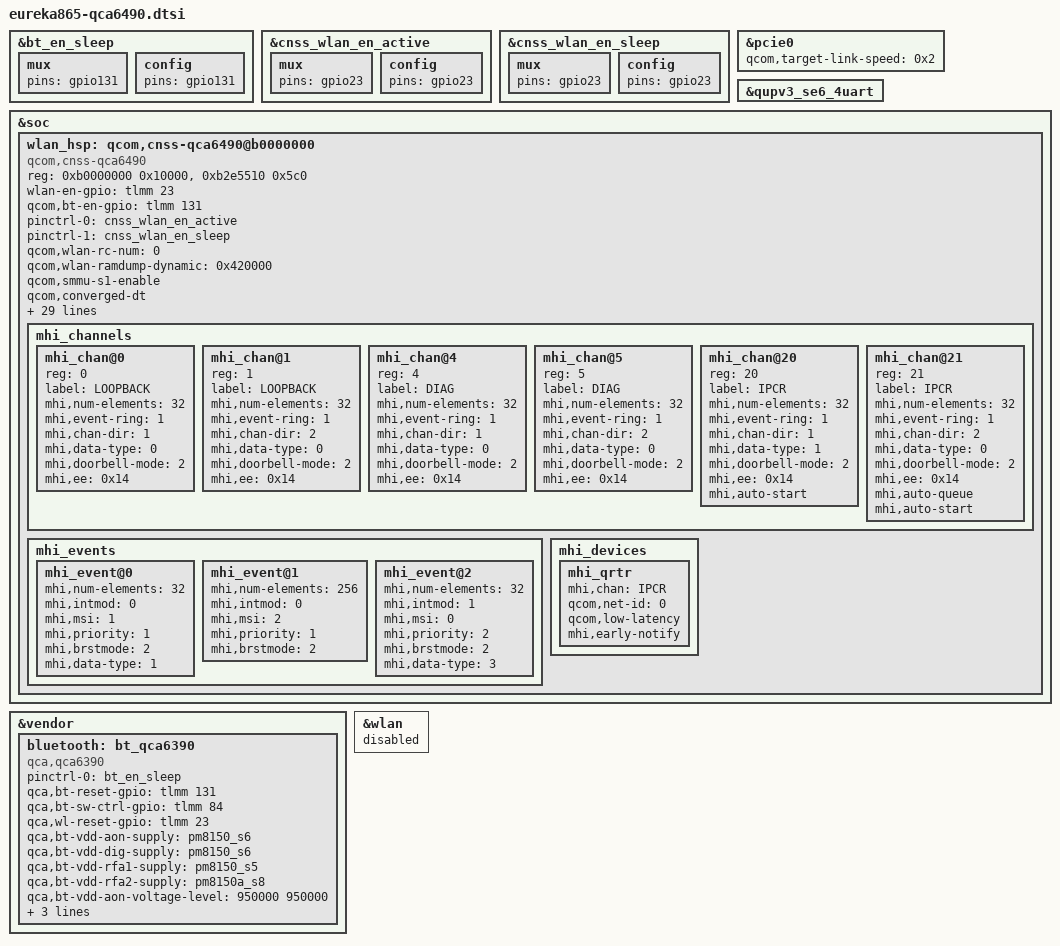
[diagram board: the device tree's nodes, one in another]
#include <dt-bindings/msm/msm-bus-ids.h>

&bt_en_sleep {
	mux {
		pins = "gpio131";
	};

	config {
		pins = "gpio131";
	};
};

&cnss_wlan_en_active {
	mux {
		pins = "gpio23";
	};

	config {
		pins = "gpio23";
	};
};

&cnss_wlan_en_sleep {
	mux {
		pins = "gpio23";
	};

	config {
		pins = "gpio23";
	};
};

&pcie0 {
	qcom,target-link-speed = <0x2>;
};

&qupv3_se6_4uart {
	status = "ok";
};

&soc {
	wlan_hsp: qcom,cnss-qca6490@b0000000 {
		compatible = "qcom,cnss-qca6490";
		reg = <0xb0000000 0x10000>,
		      <0xb2e5510 0x5c0>;
		reg-names = "smmu_iova_ipa", "tcs_cmd";
		wlan-en-gpio = <&tlmm 23 0>;
		qcom,bt-en-gpio = <&tlmm 131 0>;
		pinctrl-names = "wlan_en_active", "wlan_en_sleep";
		pinctrl-0 = <&cnss_wlan_en_active>;
		pinctrl-1 = <&cnss_wlan_en_sleep>;
		qcom,wlan-rc-num = <0>;
		qcom,wlan-ramdump-dynamic = <0x420000>;
		qcom,smmu-s1-enable;
		qcom,converged-dt;
		cnss-daemon-support;
		qcom,cmd_db_name = "smpa6";
		qcom,set-wlaon-pwr-ctrl;

		qcom,msm-bus,name = "msm-cnss";
		qcom,msm-bus,num-cases = <6>;
		qcom,msm-bus,num-paths = <1>;
		qcom,msm-bus,vectors-KBps =
		/* no vote */
		<MSM_BUS_MASTER_PCIE MSM_BUS_SLAVE_FIRST 0 0>,
		/* idle: 0-18 Mbps, ddr freq: 451.2 MHz */
		<MSM_BUS_MASTER_PCIE MSM_BUS_SLAVE_FIRST 2250 1600000>,
		/* low: 18-60 Mbps, ddr freq: 451.2 MHz*/
		<MSM_BUS_MASTER_PCIE MSM_BUS_SLAVE_FIRST 7500 1600000>,
		/* medium: 60-240 Mbps, ddr freq: 451.2 MHz */
		<MSM_BUS_MASTER_PCIE MSM_BUS_SLAVE_FIRST 30000 1804800>,
		/* high: 240 - 800 Mbps, ddr freq: 451.2 MHz */
		<MSM_BUS_MASTER_PCIE MSM_BUS_SLAVE_FIRST 100000 1804800>,
		/* very high: 800 - 1400 Mbps, ddr freq: 1555.2 MHz */
		<MSM_BUS_MASTER_PCIE MSM_BUS_SLAVE_FIRST 175000 6220800>;

		vdd-wlan-aon-supply = <&pm8150_s6>;
		qcom,vdd-wlan-aon-config = <950000 950000 0 0 1>;
		vdd-wlan-dig-supply = <&pm8150_s6>;
		qcom,vdd-wlan-dig-config = <950000 952000 0 0 1>;
		vdd-wlan-io-supply = <&pm8150_s4>;
		qcom,vdd-wlan-io-config = <1800000 1800000 0 0 1>;
		vdd-wlan-rfa1-supply = <&pm8150_s5>;
		qcom,vdd-wlan-rfa1-config = <1900000 1900000 0 0 1>;
		vdd-wlan-rfa2-supply = <&pm8150a_s8>;
		qcom,vdd-wlan-rfa2-config = <1350000 1350000 0 0 1>;

		mhi,max-channels = <30>;
		mhi,timeout = <10000>;
		mhi,buffer-len = <0x8000>;
		mhi,m2-no-db-access;

		mhi_channels {
			#address-cells = <1>;
			#size-cells = <0>;

			mhi_chan@0 {
				reg = <0>;
				label = "LOOPBACK";
				mhi,num-elements = <32>;
				mhi,event-ring = <1>;
				mhi,chan-dir = <1>;
				mhi,data-type = <0>;
				mhi,doorbell-mode = <2>;
				mhi,ee = <0x14>;
			};

			mhi_chan@1 {
				reg = <1>;
				label = "LOOPBACK";
				mhi,num-elements = <32>;
				mhi,event-ring = <1>;
				mhi,chan-dir = <2>;
				mhi,data-type = <0>;
				mhi,doorbell-mode = <2>;
				mhi,ee = <0x14>;
			};

			mhi_chan@4 {
				reg = <4>;
				label = "DIAG";
				mhi,num-elements = <32>;
				mhi,event-ring = <1>;
				mhi,chan-dir = <1>;
				mhi,data-type = <0>;
				mhi,doorbell-mode = <2>;
				mhi,ee = <0x14>;
			};

			mhi_chan@5 {
				reg = <5>;
				label = "DIAG";
				mhi,num-elements = <32>;
				mhi,event-ring = <1>;
				mhi,chan-dir = <2>;
				mhi,data-type = <0>;
				mhi,doorbell-mode = <2>;
				mhi,ee = <0x14>;
			};

			mhi_chan@20 {
				reg = <20>;
				label = "IPCR";
				mhi,num-elements = <32>;
				mhi,event-ring = <1>;
				mhi,chan-dir = <1>;
				mhi,data-type = <1>;
				mhi,doorbell-mode = <2>;
				mhi,ee = <0x14>;
				mhi,auto-start;
			};

			mhi_chan@21 {
				reg = <21>;
				label = "IPCR";
				mhi,num-elements = <32>;
				mhi,event-ring = <1>;
				mhi,chan-dir = <2>;
				mhi,data-type = <0>;
				mhi,doorbell-mode = <2>;
				mhi,ee = <0x14>;
				mhi,auto-queue;
				mhi,auto-start;
			};
		};

		mhi_events {
			mhi_event@0 {
				mhi,num-elements = <32>;
				mhi,intmod = <0>;
				mhi,msi = <1>;
				mhi,priority = <1>;
				mhi,brstmode = <2>;
				mhi,data-type = <1>;
			};

			mhi_event@1 {
				mhi,num-elements = <256>;
				mhi,intmod = <0>;
				mhi,msi = <2>;
				mhi,priority = <1>;
				mhi,brstmode = <2>;
			};

			mhi_event@2 {
				mhi,num-elements = <32>;
				mhi,intmod = <1>;
				mhi,msi = <0>;
				mhi,priority = <2>;
				mhi,brstmode = <2>;
				mhi,data-type = <3>;
			};
		};

		mhi_devices {
			mhi_qrtr {
				mhi,chan = "IPCR";
				qcom,net-id = <0>;
				qcom,low-latency;
				mhi,early-notify;
			};
		};
	};
};

&vendor {
	bluetooth: bt_qca6390 {
		compatible = "qca,qca6390";
		pinctrl-names = "default";
		pinctrl-0 = <&bt_en_sleep>;
		qca,bt-reset-gpio = <&tlmm 131 0>; /* BT_EN */
		qca,bt-sw-ctrl-gpio = <&tlmm 84 0>; /* SW_CTRL */
		qca,wl-reset-gpio = <&tlmm 23 0>; /* WL_EN */
		qca,bt-vdd-aon-supply = <&pm8150_s6>;
		qca,bt-vdd-dig-supply = <&pm8150_s6>;
		qca,bt-vdd-rfa1-supply = <&pm8150_s5>;
		qca,bt-vdd-rfa2-supply = <&pm8150a_s8>;

		qca,bt-vdd-aon-voltage-level = <950000 950000>;
		qca,bt-vdd-dig-voltage-level = <950000 952000>;
		qca,bt-vdd-rfa1-voltage-level = <1900000 1900000>;
		qca,bt-vdd-rfa2-voltage-level = <1350000 1350000>;
	};
};

&wlan {
	status = "disabled";
};
